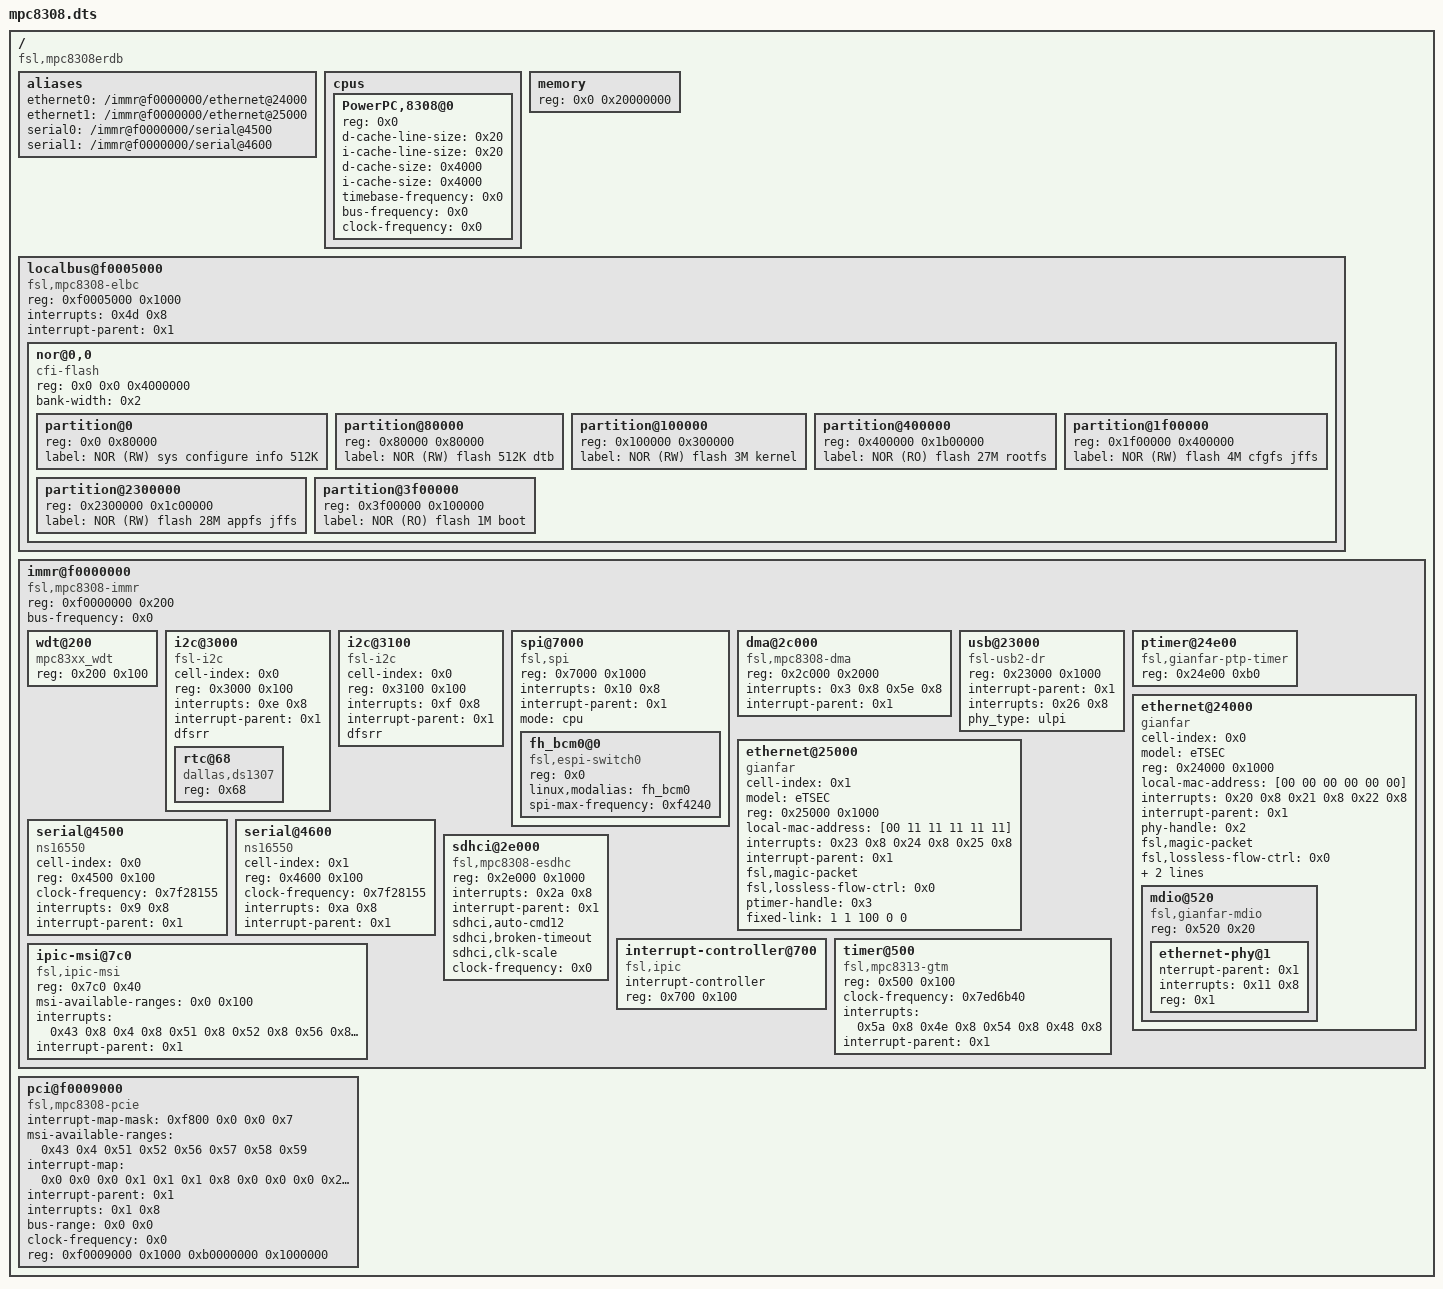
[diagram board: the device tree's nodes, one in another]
/* MXP dtb by xx */
/dts-v1/;

/ {
	compatible = "fsl,mpc8308erdb";
	#address-cells = <1>;
	#size-cells = <1>;

	aliases {
		ethernet0 = "/immr@f0000000/ethernet@24000";
		ethernet1 = "/immr@f0000000/ethernet@25000";
		serial0 = "/immr@f0000000/serial@4500";
		serial1 = "/immr@f0000000/serial@4600";
	};

	cpus {
		#address-cells = <0x1>;
		#size-cells = <0x0>;

		PowerPC,8308@0 {
			device_type = "cpu";
			reg = <0x0>;
			d-cache-line-size = <0x20>;
			i-cache-line-size = <0x20>;
			d-cache-size = <0x4000>;
			i-cache-size = <0x4000>;
			timebase-frequency = <0x0>;
			bus-frequency = <0x0>;
			clock-frequency = <0x0>;
		};
	};

	memory {
		device_type = "memory";
		reg = <0x0 0x20000000>;
	};

	localbus@f0005000 {
		#address-cells = <0x2>;
		#size-cells = <0x1>;
		compatible = "fsl,mpc8308-elbc", "fsl,elbc", "simple-bus";
		reg = <0xf0005000 0x1000>;
		interrupts = <0x4d 0x8>;
		interrupt-parent = <0x1>;
		ranges = <0x0 0x0 0xfc000000 0x4000000>;

		nor@0,0 {
			#address-cells = <0x1>;
			#size-cells = <0x1>;
			compatible = "cfi-flash";
			reg = <0x0 0x0 0x4000000>;
			bank-width = <0x2>;

			partition@0 {
				reg = <0x0 0x80000>;
				label = "NOR (RW)  sys configure info 512K";
			};

			partition@80000 {
				reg = <0x80000 0x80000>;
				label = "NOR (RW) flash 512K dtb";
			};

			partition@100000 {
				reg = <0x100000 0x300000>;
				label = "NOR (RW) flash 3M kernel";
			};

			partition@400000 {
				reg = <0x400000 0x1b00000>;
				label = "NOR (RO) flash 27M rootfs";
			};

			partition@1f00000 {
				reg = <0x1f00000 0x400000>;
				label = "NOR (RW) flash 4M cfgfs jffs";
			};

			partition@2300000 {
				reg = <0x2300000 0x1c00000>;
				label = "NOR (RW) flash 28M appfs jffs";
			};

			partition@3f00000 {
				reg = <0x3f00000 0x100000>;
				label = "NOR (RO) flash 1M boot";
			};
		};
	};

	immr@f0000000 {
		#address-cells = <0x1>;
		#size-cells = <0x1>;
		device_type = "soc";
		compatible = "fsl,mpc8308-immr", "simple-bus";
		ranges = <0x0 0xf0000000 0x100000>;
		reg = <0xf0000000 0x200>;
		bus-frequency = <0x0>;

		wdt@200 {
			device_type = "watchdog";
			compatible = "mpc83xx_wdt";
			reg = <0x200 0x100>;
		};

		i2c@3000 {
			#address-cells = <0x1>;
			#size-cells = <0x0>;
			cell-index = <0x0>;
			compatible = "fsl-i2c";
			reg = <0x3000 0x100>;
			interrupts = <0xe 0x8>;
			interrupt-parent = <0x1>;
			dfsrr;

			rtc@68 {
				compatible = "dallas,ds1307";
				reg = <0x68>;
			};
		};

		i2c@3100 {
			#address-cells = <0x1>;
			#size-cells = <0x0>;
			cell-index = <0x0>;
			compatible = "fsl-i2c";
			reg = <0x3100 0x100>;
			interrupts = <0xf 0x8>;
			interrupt-parent = <0x1>;
			dfsrr;
		};

		spi@7000 {
			#address-cells = <0x1>;
			#size-cells = <0x0>;
			compatible = "fsl,spi";
			reg = <0x7000 0x1000>;
			interrupts = <0x10 0x8>;
			interrupt-parent = <0x1>;
			mode = "cpu";

			fh_bcm0@0 {
				compatible = "fsl,espi-switch0";
				reg = <0x0>;
				linux,modalias = "fh_bcm0";
				spi-max-frequency = <0xf4240>;
			};
		};

		dma@2c000 {
			compatible = "fsl,mpc8308-dma", "fsl,mpc5121-dma";
			reg = <0x2c000 0x2000>;
			interrupts = <0x3 0x8 0x5e 0x8>;
			interrupt-parent = <0x1>;
		};

		usb@23000 {
			compatible = "fsl-usb2-dr";
			reg = <0x23000 0x1000>;
			#address-cells = <0x1>;
			#size-cells = <0x0>;
			interrupt-parent = <0x1>;
			interrupts = <0x26 0x8>;
			phy_type = "ulpi";
		};

		ptimer@24e00 {
			compatible = "fsl,gianfar-ptp-timer";
			reg = <0x24e00 0xb0>;
			linux,phandle = <0x3>;
		};

		ethernet@24000 {
			#address-cells = <0x1>;
			#size-cells = <0x1>;
			ranges = <0x0 0x24000 0x1000>;
			cell-index = <0x0>;
			device_type = "network";
			model = "eTSEC";
			compatible = "gianfar";
			reg = <0x24000 0x1000>;
			local-mac-address = [00 00 00 00 00 00];
			interrupts = <0x20 0x8 0x21 0x8 0x22 0x8>;
			interrupt-parent = <0x1>;
			phy-handle = <0x2>;
			fsl,magic-packet;
			fsl,lossless-flow-ctrl = <0x0>;
			ptimer-handle = <0x3>;
			phy-connection-type = "mii";

			mdio@520 {
				#address-cells = <0x1>;
				#size-cells = <0x0>;
				compatible = "fsl,gianfar-mdio";
				reg = <0x520 0x20>;

				ethernet-phy@1 {
					nterrupt-parent = <0x1>;
					interrupts = <0x11 0x8>;
					reg = <0x1>;
					device_type = "ethernet-phy";
					linux,phandle = <0x2>;
				};
			};
		};
		
		ethernet@25000 {
			#address-cells = <0x1>;
			#size-cells = <0x1>;
			ranges = <0x0 0x25000 0x1000>;
			cell-index = <0x1>;
			device_type = "network";
			model = "eTSEC";
			compatible = "gianfar";
			reg = <0x25000 0x1000>;
			local-mac-address = [00 11 11 11 11 11];
			interrupts = <0x23 0x8 0x24 0x8 0x25 0x8>;
			interrupt-parent = <0x1>;
			/*phy-handle = <0x2>;*/
			fsl,magic-packet;
			fsl,lossless-flow-ctrl = <0x0>;
			ptimer-handle = <0x3>;
			/*phy-connection-type = "mii";*/
			fixed-link = <1 1 100 0 0>;

			/*mdio@520 {
				#address-cells = <0x1>;
				#size-cells = <0x0>;
				compatible = "fsl,gianfar-mdio";
				reg = <0x520 0x20>;

				ethernet-phy@1 {
					nterrupt-parent = <0x1>;
					interrupts = <0x11 0x8>;
					reg = <0x1>;
					device_type = "ethernet-phy";
					linux,phandle = <0x2>;
				};
			};*/
		};

		serial@4500 {
			cell-index = <0x0>;
			device_type = "serial";
			compatible = "ns16550";
			reg = <0x4500 0x100>;
			clock-frequency = <0x7f28155>;
			interrupts = <0x9 0x8>;
			interrupt-parent = <0x1>;
		};

		serial@4600 {
			cell-index = <0x1>;
			device_type = "serial";
			compatible = "ns16550";
			reg = <0x4600 0x100>;
			clock-frequency = <0x7f28155>;
			interrupts = <0xa 0x8>;
			interrupt-parent = <0x1>;
		};

		sdhci@2e000 {
			compatible = "fsl,mpc8308-esdhc", "fsl,esdhc";
			reg = <0x2e000 0x1000>;
			interrupts = <0x2a 0x8>;
			interrupt-parent = <0x1>;
			sdhci,auto-cmd12;
			sdhci,broken-timeout;
			sdhci,clk-scale;
			clock-frequency = <0x0>;
		};

		interrupt-controller@700 {
			compatible = "fsl,ipic";
			interrupt-controller;
			#address-cells = <0x0>;
			#interrupt-cells = <0x2>;
			reg = <0x700 0x100>;
			device_type = "ipic";
			linux,phandle = <0x1>;
		};

		ipic-msi@7c0 {
			compatible = "fsl,ipic-msi";
			reg = <0x7c0 0x40>;
			msi-available-ranges = <0x0 0x100>;
			interrupts = <0x43 0x8 0x4 0x8 0x51 0x8 0x52 0x8 0x56 0x8 0x57 0x8 0x58 0x8 0x59 0x8>;
			interrupt-parent = <0x1>;
		};

		timer@500 {
			compatible = "fsl,mpc8313-gtm", "fsl,gtm";
			reg = <0x500 0x100>;
			clock-frequency = <0x7ed6b40>;
			interrupts = <0x5a 0x8 0x4e 0x8 0x54 0x8 0x48 0x8>;
			interrupt-parent = <0x1>;
		};
	};

	pci@f0009000 {
		interrupt-map-mask = <0xf800 0x0 0x0 0x7>;
		msi-available-ranges = <0x43 0x4 0x51 0x52 0x56 0x57 0x58 0x59>;
		interrupt-map = <0x0 0x0 0x0 0x1 0x1 0x1 0x8 0x0 0x0 0x0 0x2 0x1 0x1 0x8 0x0 0x0 0x0 0x3 0x1 0x1 0x8 0x0 0x0 0x0 0x4 0x1 0x1 0x8>;
		interrupt-parent = <0x1>;
		interrupts = <0x1 0x8>;
		bus-range = <0x0 0x0>;
		ranges = <0x2000000 0x0 0x80000000 0x80000000 0x0 0x20000000 0x1000000 0x0 0x0 0xb1000000 0x0 0x800000>;
		clock-frequency = <0x0>;
		#interrupt-cells = <0x1>;
		#size-cells = <0x2>;
		#address-cells = <0x3>;
		reg = <0xf0009000 0x1000 0xb0000000 0x1000000>;
		compatible = "fsl,mpc8308-pcie";
		device_type = "pci";
	};
};
